# APM32F427 register map
File version: 1.0
CPU: CM4 r1p0, little endian, no MPU, no FPU, 4 interrupt priority bits
Registers are 32-bit, read-write, reset 0x0 unless marked. A register's access mark holds for its fields unless they carry their own. Offsets are from the block's base; [hi:lo] are bit positions; {n}, {i} and the like mark numbered series.

## RCM — Reset and clock control
Base 0x40023800
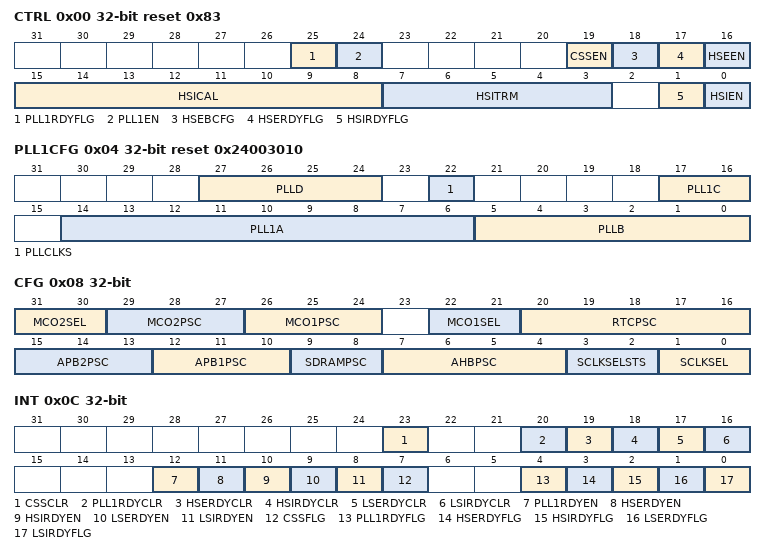
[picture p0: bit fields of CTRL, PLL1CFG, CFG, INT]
0x00 CTRL access per field reset 0x83 — clock control register
  [25] PLL1RDYFLG ro — PLL1 Clock Ready Flag
  [24] PLL1EN rw — PLL1 Enable
  [19] CSSEN rw — Clock security system enable
  [18] HSEBCFG rw — HSE clock bypass
  [17] HSERDYFLG ro — HSE clock ready flag
  [16] HSEEN rw — HSE clock enable
  [15:8] HSICAL ro — Internal high-speed clock calibration
  [7:3] HSITRM rw — Internal high-speed clock trimming
  [1] HSIRDYFLG ro — Internal high-speed clock ready flag
  [0] HSIEN rw — Internal high-speed clock enable
0x04 PLL1CFG reset 0x24003010 — PLL configuration register
  [27:24] PLLD — Division Factor D
  [22] PLLCLKS — PLL Clock Source
  [17:16] PLL1C — Division Factor C
  [14:6] PLL1A — PLL Multiplication Factor A
  [5:0] PLLB — Division Factor B
0x08 CFG access per field — clock configuration register
  [31:30] MCO2SEL rw — Microcontroller clock output 2
  [29:27] MCO2PSC rw — MCO2 prescaler
  [26:24] MCO1PSC rw — MCO1 prescaler
  [22:21] MCO1SEL rw — Microcontroller clock output 1
  [20:16] RTCPSC rw — HSE division factor for RTC clock
  [15:13] APB2PSC rw — APB high-speed prescaler (APB2)
  [12:10] APB1PSC rw — APB Low speed prescaler (APB1)
  [9:8] SDRAMPSC rw — SDRAM Clock Prescaler Factor Configure
  [7:4] AHBPSC rw — AHB prescaler
  [3:2] SCLKSELSTS ro — System clock switch status
  [1:0] SCLKSEL rw — System clock switch
0x0C INT access per field — clock interrupt register
  [23] CSSCLR wo — Clock security system interrupt clear
  [20] PLL1RDYCLR wo — Main PLL(PLL) ready interrupt clear
  [19] HSERDYCLR wo — HSE ready interrupt clear
  [18] HSIRDYCLR wo — HSI ready interrupt clear
  [17] LSERDYCLR wo — LSE ready interrupt clear
  [16] LSIRDYCLR wo — LSI ready interrupt clear
  [12] PLL1RDYEN rw — Main PLL (PLL) ready interrupt enable
  [11] HSERDYEN rw — HSE ready interrupt enable
  [10] HSIRDYEN rw — HSI ready interrupt enable
  [9] LSERDYEN rw — LSE ready interrupt enable
  [8] LSIRDYEN rw — LSI ready interrupt enable
  [7] CSSFLG ro — Clock security system interrupt flag
  [4] PLL1RDYFLG ro — Main PLL (PLL) ready interrupt flag
  [3] HSERDYFLG ro — HSE ready interrupt flag
  [2] HSIRDYFLG ro — HSI ready interrupt flag
  [1] LSERDYFLG ro — LSE ready interrupt flag
  [0] LSIRDYFLG ro — LSI ready interrupt flag
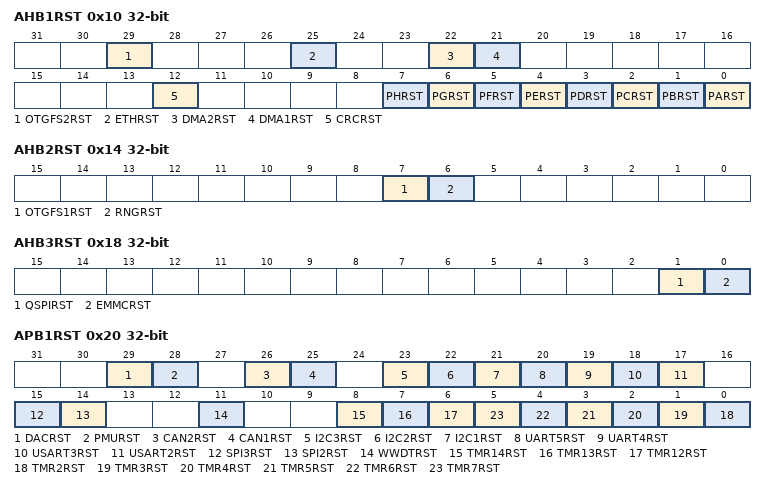
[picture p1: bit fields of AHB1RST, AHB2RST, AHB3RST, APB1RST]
0x10 AHB1RST — AHB1 peripheral reset register
  [29] OTGFS2RST — OTG_FS2 Reset
  [25] ETHRST — Ethernet MAC reset
  [22] DMA2RST — DMA2 reset
  [21] DMA1RST — DMA2 reset
  [12] CRCRST — CRC reset
  [7] PHRST — IO port H reset
  [6] PGRST — IO port G reset
  [5] PFRST — IO port F reset
  [4] PERST — IO port E reset
  [3] PDRST — IO port D reset
  [2] PCRST — IO port C reset
  [1] PBRST — IO port B reset
  [0] PARST — IO port A reset
0x14 AHB2RST — AHB2 peripheral reset register
  [7] OTGFS1RST — OTG_FS1 Reset
  [6] RNGRST — RNG Reset
0x18 AHB3RST — AHB3 peripheral reset register
  [1] QSPIRST — QSPI reset
  [0] EMMCRST — Flexible static memory controller module reset
0x20 APB1RST — APB1 peripheral reset register
  [29] DACRST — DAC reset
  [28] PMURST — PMU Clock reset
  [26] CAN2RST — CAN2 reset
  [25] CAN1RST — CAN1 reset
  [23] I2C3RST — I2C3 reset
  [22] I2C2RST — I2C 2 reset
  [21] I2C1RST — I2C 1 reset
  [20] UART5RST — UART 5 reset
  [19] UART4RST — UART 4 reset
  [18] USART3RST — USART 3 reset
  [17] USART2RST — USART 2 reset
  [15] SPI3RST — SPI 3 reset
  [14] SPI2RST — SPI 2 reset
  [11] WWDTRST — WWDT Reset
  [8] TMR14RST — TMR14 reset
  [7] TMR13RST — TMR13 reset
  [6] TMR12RST — TMR12 reset
  [n-2] TMR{n}RST (n=2..7) — TMR{n} reset
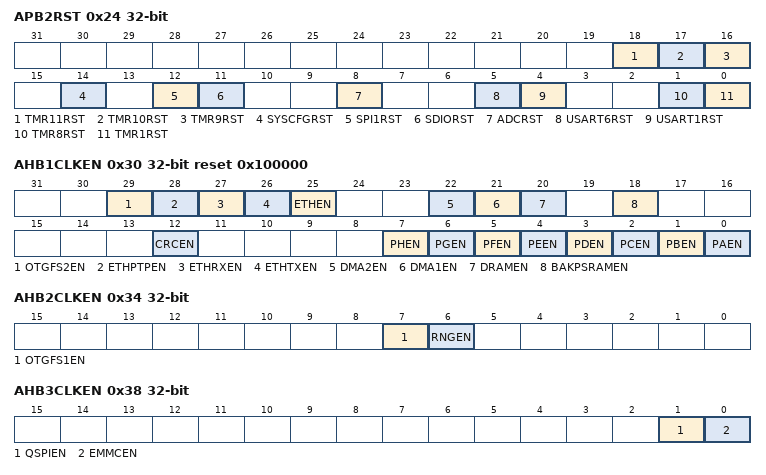
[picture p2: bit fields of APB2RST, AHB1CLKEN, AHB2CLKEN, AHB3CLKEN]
0x24 APB2RST — APB2 peripheral reset register
  [18] TMR11RST — TMR11 reset
  [17] TMR10RST — TMR10 reset
  [16] TMR9RST — TMR9 reset
  [14] SYSCFGRST — SYSCFG Module Reset
  [12] SPI1RST — SPI 1 reset
  [11] SDIORST — SDIO reset
  [8] ADCRST — ADC Interface Reset
  [5] USART6RST — USART6 reset
  [4] USART1RST — USART1 reset
  [1] TMR8RST — TMR8 reset
  [0] TMR1RST — TMR1 reset
0x30 AHB1CLKEN reset 0x100000 — AHB1 peripheral clock register
  [29] OTGFS2EN — USB OTG FS2 clock enable
  [28] ETHPTPEN — Ethernet PTP clock enable
  [27] ETHRXEN — Ethernet Reception clock enable
  [26] ETHTXEN — Ethernet Transmission clock enable
  [25] ETHEN — Ethernet MAC clock enable
  [22] DMA2EN — DMA2 clock enable
  [21] DMA1EN — DMA1 clock enable
  [20] DRAMEN — Clock Management Data RAM Clock Enable
  [18] BAKPSRAMEN — Backup SRAM interface clock enable
  [12] CRCEN — CRC clock enable
  [7] PHEN — IO port H clock enable
  [6] PGEN — IO port G clock enable
  [5] PFEN — IO port F clock enable
  [4] PEEN — IO port E clock enable
  [3] PDEN — IO port D clock enable
  [2] PCEN — IO port C clock enable
  [1] PBEN — IO port B clock enable
  [0] PAEN — IO port A clock enable
0x34 AHB2CLKEN — AHB2 peripheral clock enable register
  [7] OTGFS1EN — USB OTG FS1 clock enable
  [6] RNGEN — Random number generator clock enable
0x38 AHB3CLKEN — AHB3 peripheral clock enable register
  [1] QSPIEN — QSPI Clock Enable
  [0] EMMCEN — EMMC Clock Enable
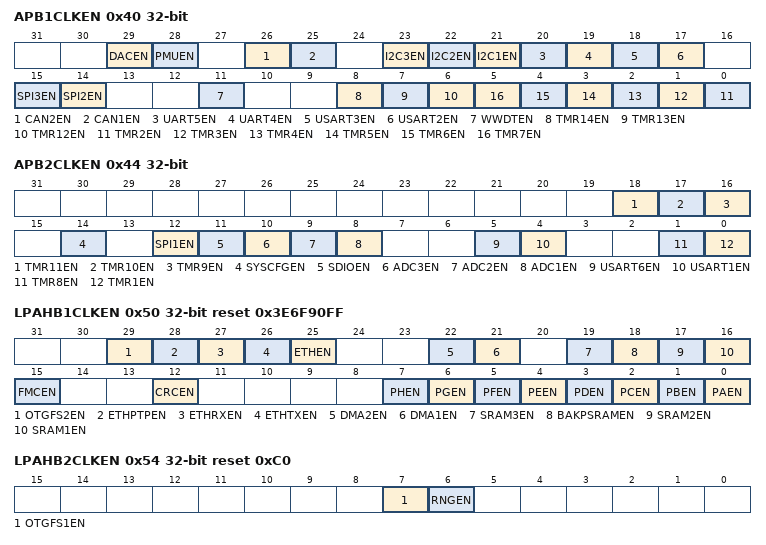
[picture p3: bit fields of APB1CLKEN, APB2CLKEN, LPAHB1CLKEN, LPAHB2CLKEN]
0x40 APB1CLKEN — APB1 peripheral clock enable register
  [29] DACEN — DAC interface clock enable
  [28] PMUEN — PMU Clock Enable
  [26] CAN2EN — CAN 2 clock enable
  [25] CAN1EN — CAN 1 clock enable
  [23] I2C3EN — I2C3 clock enable
  [22] I2C2EN — I2C2 clock enable
  [21] I2C1EN — I2C1 clock enable
  [20] UART5EN — UART5 clock enable
  [19] UART4EN — UART4 clock enable
  [18] USART3EN — USART3 clock enable
  [17] USART2EN — USART 2 clock enable
  [15] SPI3EN — SPI3 clock enable
  [14] SPI2EN — SPI2 clock enable
  [11] WWDTEN — Window watchdog clock enable
  [8] TMR14EN — TMR14 clock enable
  [7] TMR13EN — TMR13 clock enable
  [6] TMR12EN — TMR12 clock enable
  [n-2] TMR{n}EN (n=2..7) — TMR{n} clock enable
0x44 APB2CLKEN — APB2 peripheral clock enable register
  [18] TMR11EN — TMR11 clock enable
  [17] TMR10EN — TMR10 clock enable
  [16] TMR9EN — TMR9 clock enable
  [14] SYSCFGEN — System configuration controller clock enable
  [12] SPI1EN — SPI1 clock enable
  [11] SDIOEN — SDIO clock enable
  [10] ADC3EN — ADC3 clock enable
  [9] ADC2EN — ADC2 clock enable
  [8] ADC1EN — ADC1 clock enable
  [5] USART6EN — USART6 clock enable
  [4] USART1EN — USART1 clock enable
  [1] TMR8EN — TMR8 clock enable
  [0] TMR1EN — TMR1 clock enable
0x50 LPAHB1CLKEN reset 0x3E6F90FF — AHB1 peripheral clock enable in low power mode register
  [29] OTGFS2EN — OTG_FS2 Clock Enable
  [28] ETHPTPEN — Ethernet PTP clock enable during Sleep mode
  [27] ETHRXEN — Ethernet reception clock enable during Sleep mode
  [26] ETHTXEN — Ethernet transmission clock enable during Sleep mode
  [25] ETHEN — Ethernet MAC clock enable during Sleep mode
  [22] DMA2EN — DMA2 clock enable during Sleep mode
  [21] DMA1EN — DMA1 clock enable during Sleep mode
  [19] SRAM3EN — SRAM 3 clock clock enable during Sleep mode
  [18] BAKPSRAMEN — Backup SRAM interface clock enable during Sleep mode
  [17] SRAM2EN — SRAM 2 interface clock enable during Sleep mode
  [16] SRAM1EN — SRAM 1interface clock enable during Sleep mode
  [15] FMCEN — Flash interface clock enable during Sleep mode
  [12] CRCEN — CRC clock enable during Sleep mode
  [7] PHEN — IO port H clock enable during Sleep mode
  [6] PGEN — IO port G clock enable during Sleep mode
  [5] PFEN — IO port F clock enable during Sleep mode
  [4] PEEN — IO port E clock enable during Sleep mode
  [3] PDEN — IO port D clock enable during Sleep mode
  [2] PCEN — IO port C clock enable during Sleep mode
  [1] PBEN — IO port B clock enable during Sleep mode
  [0] PAEN — IO port A clock enable during sleep mode
0x54 LPAHB2CLKEN reset 0xC0 — AHB2 peripheral clock enable in low power mode register
  [7] OTGFS1EN — USB OTG FS1 clock enable during Sleep mode
  [6] RNGEN — Random number generator clock enable during Sleep mode
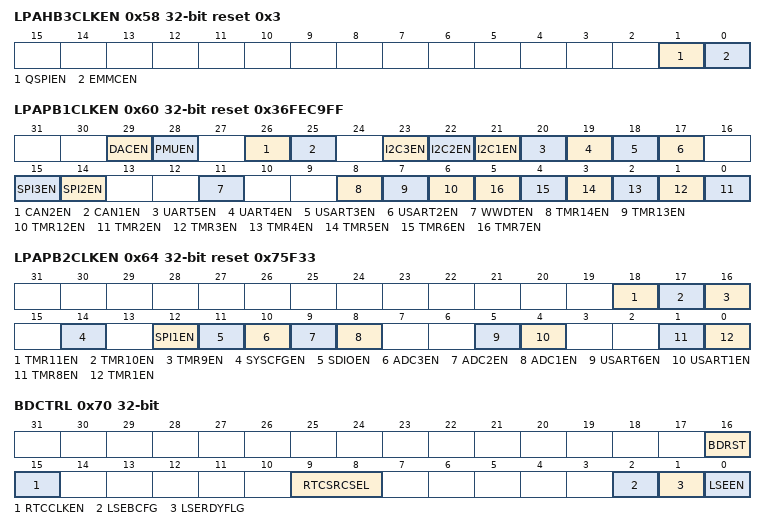
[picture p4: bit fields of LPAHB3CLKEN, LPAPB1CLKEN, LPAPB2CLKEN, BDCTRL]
0x58 LPAHB3CLKEN reset 0x3 — AHB3 peripheral clock enable in low power mode register
  [1] QSPIEN — QSPI clock enable during Sleep mode
  [0] EMMCEN — EMMC clock enable during Sleep mode
0x60 LPAPB1CLKEN reset 0x36FEC9FF — APB1 peripheral clock enable in low power mode register
  [29] DACEN — DAC interface clock enable during Sleep mode
  [28] PMUEN — Power interface clock enable during Sleep mode
  [26] CAN2EN — CAN 2 clock enable during Sleep mode
  [25] CAN1EN — CAN 1 clock enable during Sleep mode
  [23] I2C3EN — I2C3 clock enable during Sleep mode
  [22] I2C2EN — I2C2 clock enable during Sleep mode
  [21] I2C1EN — I2C1 clock enable during Sleep mode
  [20] UART5EN — UART5 clock enable during Sleep mode
  [19] UART4EN — UART4 clock enable during Sleep mode
  [18] USART3EN — USART3 clock enable during Sleep mode
  [17] USART2EN — USART2 clock enable during Sleep mode
  [15] SPI3EN — SPI3 clock enable during Sleep mode
  [14] SPI2EN — SPI2 clock enable during Sleep mode
  [11] WWDTEN — Window watchdog clock enable during Sleep mode
  [8] TMR14EN — TMR14 clock enable during Sleep mode
  [7] TMR13EN — TMR13 clock enable during Sleep mode
  [6] TMR12EN — TMR12 clock enable during Sleep mode
  [n-2] TMR{n}EN (n=2..7) — TMR{n} clock enable during Sleep mode
0x64 LPAPB2CLKEN reset 0x75F33 — APB2 peripheral clock enabled in low power mode register
  [18] TMR11EN — TMR11 clock enable during Sleep mode
  [17] TMR10EN — TMR10 clock enable during Sleep mode
  [16] TMR9EN — TMR9 clock enable during sleep mode
  [14] SYSCFGEN — System configuration controller clock enable during Sleep mode
  [12] SPI1EN — SPI 1 clock enable during Sleep mode
  [11] SDIOEN — SDIO clock enable during Sleep mode
  [10] ADC3EN — ADC 3 clock enable during Sleep mode
  [9] ADC2EN — ADC2 clock enable during Sleep mode
  [8] ADC1EN — ADC1 clock enable during Sleep mode
  [5] USART6EN — USART6 clock enable during Sleep mode
  [4] USART1EN — USART1 clock enable during Sleep mode
  [1] TMR8EN — TMR8 clock enable during Sleep mode
  [0] TMR1EN — TMR1 clock enable during Sleep mode
0x70 BDCTRL access per field — Backup domain control register
  [16] BDRST rw — Backup domain software reset
  [15] RTCCLKEN rw — RTC clock enable
  [9:8] RTCSRCSEL rw — RTC clock source selection
  [2] LSEBCFG rw — External low-speed oscillator bypass
  [1] LSERDYFLG ro — External low-speed oscillator ready
  [0] LSEEN rw — External low-speed oscillator enable
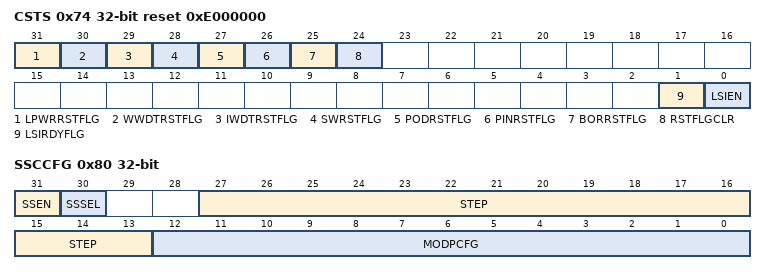
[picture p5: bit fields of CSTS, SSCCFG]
0x74 CSTS access per field reset 0xE000000 — clock control & status register
  [31] LPWRRSTFLG ro — Low-power reset flag
  [30] WWDTRSTFLG ro — Window watchdog reset flag
  [29] IWDTRSTFLG ro — Independent watchdog reset flag
  [28] SWRSTFLG ro — Software reset flag
  [27] PODRSTFLG ro — POR/PDR reset flag
  [26] PINRSTFLG ro — PIN reset flag
  [25] BORRSTFLG ro — BOR reset flag
  [24] RSTFLGCLR rw — Remove reset flag
  [1] LSIRDYFLG ro — Internal low-speed oscillator ready
  [0] LSIEN rw — Internal low-speed oscillator enable
0x80 SSCCFG — spread spectrum clock generation register
  [31] SSEN — Spread spectrum modulation enable
  [30] SSSEL — Spread Select
  [27:13] STEP — Incrementation step
  [12:0] MODPCFG — Modulation period
